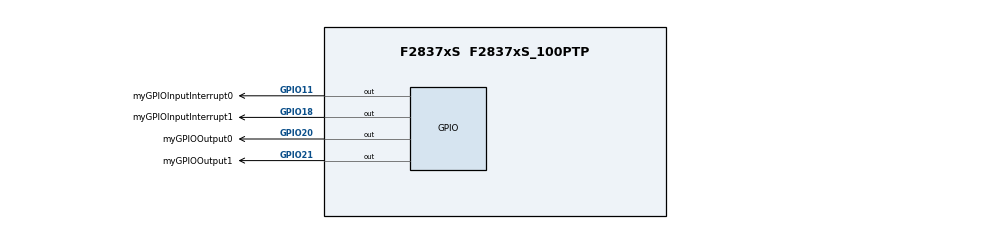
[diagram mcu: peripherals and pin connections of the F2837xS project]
/**
 * @cliArgs --device "F2837xS" --package "F2837xS_100PTP" --part "F2837xS_100PTP" --product "C2000WARE@3.00.00.00"
 * @versions {"data":"2020052512","timestamp":"2020052512","tool":"1.5.0+1397","templates":"2020052512"}
 */

/**
 * Import the modules used in this configuration.
 */
const gpio  = scripting.addModule("/driverlib/gpio.js", {}, false);
const gpio1 = gpio.addInstance();
const gpio2 = gpio.addInstance();
const gpio3 = gpio.addInstance();
const gpio4 = gpio.addInstance();

/**
 * Write custom configuration values to the imported modules.
 */
gpio1.$name           = "myGPIOInputInterrupt0";
gpio1.padConfig       = "PULLUP";
gpio1.gpioPin.$assign = "GPIO11";

gpio2.$name           = "myGPIOOutput0";
gpio2.direction       = "GPIO_DIR_MODE_OUT";
gpio2.gpioPin.$assign = "GPIO20";

gpio3.$name           = "myGPIOOutput1";
gpio3.direction       = "GPIO_DIR_MODE_OUT";
gpio3.gpioPin.$assign = "GPIO21";

gpio4.$name           = "myGPIOInputInterrupt1";
gpio4.padConfig       = "PULLUP";
gpio4.gpioPin.$assign = "GPIO18";
